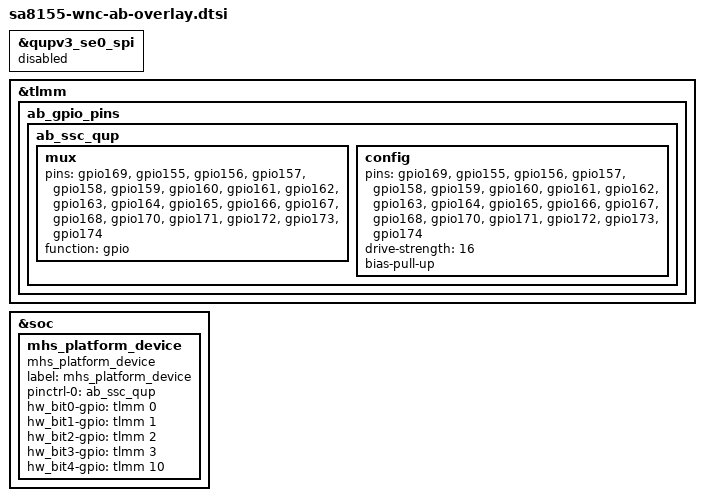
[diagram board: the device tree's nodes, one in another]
/* Copyright (c) 2017-2018, The Linux Foundation. All rights reserved.
 *
 * This program is free software; you can redistribute it and/or modify
 * it under the terms of the GNU General Public License version 2 and
 * only version 2 as published by the Free Software Foundation.
 *
 * This program is distributed in the hope that it will be useful,
 * but WITHOUT ANY WARRANTY; without even the implied warranty of
 * MERCHANTABILITY or FITNESS FOR A PARTICULAR PURPOSE.  See the
 * GNU General Public License for more details.
 */


&qupv3_se0_spi {
	status = "disabled";
};


&tlmm {

	ab_gpio_pins {
	
		ab_ssc_qup: ab_ssc_qup {
			mux {
				pins = "gpio169", "gpio155", "gpio156", "gpio157", "gpio158", "gpio159", "gpio160", "gpio161", "gpio162", "gpio163", "gpio164", "gpio165", "gpio166", "gpio167", "gpio168","gpio170","gpio171","gpio172","gpio173","gpio174";
				function = "gpio";
			};

			config {
				pins = "gpio169", "gpio155", "gpio156", "gpio157", "gpio158", "gpio159", "gpio160", "gpio161", "gpio162", "gpio163", "gpio164", "gpio165", "gpio166", "gpio167", "gpio168","gpio170","gpio171","gpio172","gpio173","gpio174";
				drive-strength = <16>;
				bias-pull-up;
			};	
		
		};

	};


};

&soc {
	mhs_platform_device {
		compatible = "mhs_platform_device";
		label = "mhs_platform_device";
		pinctrl-names = "wnc_ab_gpio";
		pinctrl-0 = <&ab_ssc_qup>;

		hw_bit0-gpio = <&tlmm 0 0>;
		hw_bit1-gpio = <&tlmm 1 0>;
		hw_bit2-gpio = <&tlmm 2 0>;
		hw_bit3-gpio = <&tlmm 3 0>;
		hw_bit4-gpio = <&tlmm 10 0>;
		
		status = "ok";
	};
};

